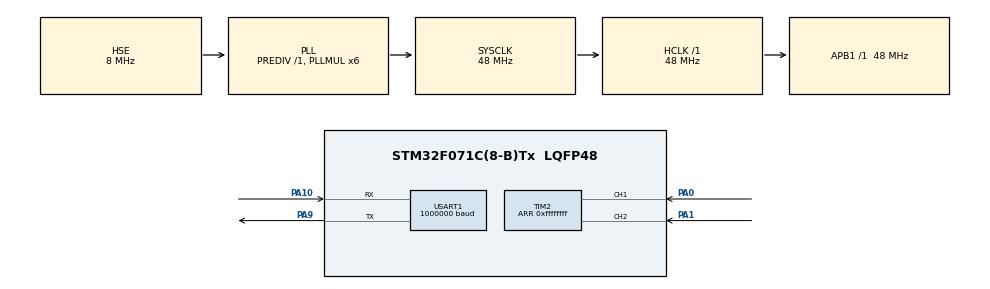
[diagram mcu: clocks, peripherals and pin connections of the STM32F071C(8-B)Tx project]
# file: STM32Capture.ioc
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Mcu.Family=STM32F0
RCC.PLLSourceVirtual=RCC_PLLSOURCE_HSE
PA10.Mode=Asynchronous
TIM2.IC1Filter=5
USART1.BaudRate=1000000
TIM2.EncoderMode=TIM_ENCODERMODE_TI12
RCC.SYSCLKSource=RCC_SYSCLKSOURCE_PLLCLK
ProjectManager.StackSize=0x400
PA0.GPIO_Speed=GPIO_SPEED_FREQ_HIGH
USART1.VirtualMode-Asynchronous=VM_ASYNC
SH.S_TIM2_CH2.0=TIM2_CH2,Encoder_Interface
PA9.Mode=Asynchronous
ProjectManager.TargetToolchain=MDK-ARM V5
RCC.HCLKFreq_Value=48000000
TIM3.Period=10000 - 1
PA9.Signal=USART1_TX
PA1.GPIO_PuPd=GPIO_NOPULL
PA1.Signal=S_TIM2_CH2
RCC.AHBFreq_Value=48000000
PF0-OSC_IN.Mode=HSE-External-Oscillator
board=custom
RCC.PLLMUL=RCC_PLL_MUL6
NVIC.TIM3_IRQn=true\:0\:0\:false\:false\:true\:true\:true
TIM2.IC2Polarity=TIM_ICPOLARITY_FALLING
PA1.GPIO_Speed=GPIO_SPEED_FREQ_HIGH
TIM3.Prescaler=48-1
TIM2.Period=0xffffffff
Mcu.Name=STM32F071C(8-B)Tx
PA0.Signal=S_TIM2_CH1_ETR
RCC.SYSCLKFreq_VALUE=48000000
Mcu.Package=LQFP48
PA0.GPIO_PuPd=GPIO_NOPULL
TIM2.IC1Polarity=TIM_ICPOLARITY_RISING
SH.S_TIM2_CH1_ETR.0=TIM2_CH1,Encoder_Interface
PA10.Signal=USART1_RX
ProjectManager.HeapSize=0x200
RCC.APB1TimFreq_Value=48000000
PF0-OSC_IN.Signal=RCC_OSC_IN
PF1-OSC_OUT.Mode=HSE-External-Oscillator
RCC.APB1Freq_Value=48000000
VP_TIM3_VS_ClockSourceINT.Mode=Internal
PF1-OSC_OUT.Signal=RCC_OSC_OUT
TIM2.IC2Filter=5

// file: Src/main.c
/* USER CODE BEGIN Header */
/**
  ******************************************************************************
  * @file           : main.c
  * @brief          : Main program body
  ******************************************************************************
  * @attention
  *
  * <h2><center>&copy; Copyright (c) 2020 STMicroelectronics.
  * All rights reserved.</center></h2>
  *
  * This software component is licensed by ST under BSD 3-Clause license,
  * the "License"; You may not use this file except in compliance with the
  * License. You may obtain a copy of the License at:
  *                        opensource.org/licenses/BSD-3-Clause
  *
  ******************************************************************************
  */
/* USER CODE END Header */

#include "main.h"

/* USER CODE BEGIN Includes */
#include "stdio.h"
/* USER CODE END Includes */

TIM_HandleTypeDef htim2;
TIM_HandleTypeDef htim3;

UART_HandleTypeDef huart1;

void SystemClock_Config(void);
static void MX_GPIO_Init(void);
static void MX_TIM2_Init(void);
static void MX_TIM3_Init(void);
static void MX_USART1_UART_Init(void);

/* USER CODE BEGIN 0 */

int fputc(int ch,FILE *f)
{
    uint8_t temp[1]={ch};
    HAL_UART_Transmit(&huart1,temp,1,2);
		return 0;
}

int32_t cnt=0;
void HAL_TIM_PeriodElapsedCallback(TIM_HandleTypeDef *htim)
{
	cnt = TIM2->CNT;
	TIM2->CNT = 0;
	//cnt = cnt /20000 * 360 /0.01 ;
	cnt = cnt * 0.3;
	printf("Line1=%d;\r\n",cnt);
}
/* USER CODE END 0 */

int main(void)
{

  /* MCU Configuration--------------------------------------------------------*/

  /* Reset of all peripherals, Initializes the Flash interface and the Systick. */
  HAL_Init();

  /* Configure the system clock */
  SystemClock_Config();

  /* Initialize all configured peripherals */
  MX_GPIO_Init();
  MX_TIM2_Init();
  MX_TIM3_Init();
  MX_USART1_UART_Init();
  /* USER CODE BEGIN 2 */
	HAL_TIM_Encoder_Start(&htim2, TIM_CHANNEL_ALL);
	HAL_TIM_Base_Start_IT(&htim3);

  /* USER CODE END 2 */

  /* Infinite loop */
  while (1)
  {

  }
}

void SystemClock_Config(void)
{
  RCC_OscInitTypeDef RCC_OscInitStruct = {0};
  RCC_ClkInitTypeDef RCC_ClkInitStruct = {0};
  RCC_PeriphCLKInitTypeDef PeriphClkInit = {0};

  /** Initializes the CPU, AHB and APB busses clocks
  */
  RCC_OscInitStruct.OscillatorType = RCC_OSCILLATORTYPE_HSE;
  RCC_OscInitStruct.HSEState = RCC_HSE_ON;
  RCC_OscInitStruct.PLL.PLLState = RCC_PLL_ON;
  RCC_OscInitStruct.PLL.PLLSource = RCC_PLLSOURCE_HSE;
  RCC_OscInitStruct.PLL.PLLMUL = RCC_PLL_MUL6;
  RCC_OscInitStruct.PLL.PREDIV = RCC_PREDIV_DIV1;
  if (HAL_RCC_OscConfig(&RCC_OscInitStruct) != HAL_OK)
  {
    Error_Handler();
  }
  /** Initializes the CPU, AHB and APB busses clocks
  */
  RCC_ClkInitStruct.ClockType = RCC_CLOCKTYPE_HCLK|RCC_CLOCKTYPE_SYSCLK
                              |RCC_CLOCKTYPE_PCLK1;
  RCC_ClkInitStruct.SYSCLKSource = RCC_SYSCLKSOURCE_PLLCLK;
  RCC_ClkInitStruct.AHBCLKDivider = RCC_SYSCLK_DIV1;
  RCC_ClkInitStruct.APB1CLKDivider = RCC_HCLK_DIV1;

  if (HAL_RCC_ClockConfig(&RCC_ClkInitStruct, FLASH_LATENCY_1) != HAL_OK)
  {
    Error_Handler();
  }
  PeriphClkInit.PeriphClockSelection = RCC_PERIPHCLK_USART1;
  PeriphClkInit.Usart1ClockSelection = RCC_USART1CLKSOURCE_PCLK1;
  if (HAL_RCCEx_PeriphCLKConfig(&PeriphClkInit) != HAL_OK)
  {
    Error_Handler();
  }
}

static void MX_TIM2_Init(void)
{

  TIM_Encoder_InitTypeDef sConfig = {0};
  TIM_MasterConfigTypeDef sMasterConfig = {0};

  htim2.Instance = TIM2;
  htim2.Init.Prescaler = 0;
  htim2.Init.CounterMode = TIM_COUNTERMODE_UP;
  htim2.Init.Period = 0xffffffff;
  htim2.Init.ClockDivision = TIM_CLOCKDIVISION_DIV1;
  htim2.Init.AutoReloadPreload = TIM_AUTORELOAD_PRELOAD_DISABLE;
  sConfig.EncoderMode = TIM_ENCODERMODE_TI12;
  sConfig.IC1Polarity = TIM_ICPOLARITY_RISING;
  sConfig.IC1Selection = TIM_ICSELECTION_DIRECTTI;
  sConfig.IC1Prescaler = TIM_ICPSC_DIV1;
  sConfig.IC1Filter = 5;
  sConfig.IC2Polarity = TIM_ICPOLARITY_FALLING;
  sConfig.IC2Selection = TIM_ICSELECTION_DIRECTTI;
  sConfig.IC2Prescaler = TIM_ICPSC_DIV1;
  sConfig.IC2Filter = 5;
  if (HAL_TIM_Encoder_Init(&htim2, &sConfig) != HAL_OK)
  {
    Error_Handler();
  }
  sMasterConfig.MasterOutputTrigger = TIM_TRGO_RESET;
  sMasterConfig.MasterSlaveMode = TIM_MASTERSLAVEMODE_DISABLE;
  if (HAL_TIMEx_MasterConfigSynchronization(&htim2, &sMasterConfig) != HAL_OK)
  {
    Error_Handler();
  }

}

static void MX_TIM3_Init(void)
{

  TIM_ClockConfigTypeDef sClockSourceConfig = {0};
  TIM_MasterConfigTypeDef sMasterConfig = {0};

  htim3.Instance = TIM3;
  htim3.Init.Prescaler = 48-1;
  htim3.Init.CounterMode = TIM_COUNTERMODE_UP;
  htim3.Init.Period = 10000 - 1;
  htim3.Init.ClockDivision = TIM_CLOCKDIVISION_DIV1;
  htim3.Init.AutoReloadPreload = TIM_AUTORELOAD_PRELOAD_DISABLE;
  if (HAL_TIM_Base_Init(&htim3) != HAL_OK)
  {
    Error_Handler();
  }
  sClockSourceConfig.ClockSource = TIM_CLOCKSOURCE_INTERNAL;
  if (HAL_TIM_ConfigClockSource(&htim3, &sClockSourceConfig) != HAL_OK)
  {
    Error_Handler();
  }
  sMasterConfig.MasterOutputTrigger = TIM_TRGO_RESET;
  sMasterConfig.MasterSlaveMode = TIM_MASTERSLAVEMODE_DISABLE;
  if (HAL_TIMEx_MasterConfigSynchronization(&htim3, &sMasterConfig) != HAL_OK)
  {
    Error_Handler();
  }

}

static void MX_USART1_UART_Init(void)
{

  huart1.Instance = USART1;
  huart1.Init.BaudRate = 1000000;
  huart1.Init.WordLength = UART_WORDLENGTH_8B;
  huart1.Init.StopBits = UART_STOPBITS_1;
  huart1.Init.Parity = UART_PARITY_NONE;
  huart1.Init.Mode = UART_MODE_TX_RX;
  huart1.Init.HwFlowCtl = UART_HWCONTROL_NONE;
  huart1.Init.OverSampling = UART_OVERSAMPLING_16;
  huart1.Init.OneBitSampling = UART_ONE_BIT_SAMPLE_DISABLE;
  huart1.AdvancedInit.AdvFeatureInit = UART_ADVFEATURE_NO_INIT;
  if (HAL_UART_Init(&huart1) != HAL_OK)
  {
    Error_Handler();
  }

}

static void MX_GPIO_Init(void)
{

  /* GPIO Ports Clock Enable */
  __HAL_RCC_GPIOF_CLK_ENABLE();
  __HAL_RCC_GPIOA_CLK_ENABLE();

}

void Error_Handler(void)
{
}

/************************ (C) COPYRIGHT STMicroelectronics *****END OF FILE****/
